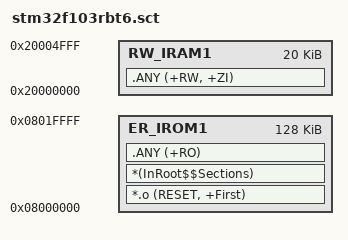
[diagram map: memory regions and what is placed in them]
; *************************************************************
; *** Scatter-Loading Description File generated by uVision ***
; *************************************************************

LR_IROM1 0x08000000 0x00020000  {    ; load region size_region  0x0003D000  0x0007D000
ER_IROM1 0x08000000 0x00020000  {  ; load address = execution address  0x0003D000  0x0007D000
   *.o (RESET, +First)
   *(InRoot$$Sections)
   .ANY (+RO)
  }
  RW_IRAM1 0x20000000 0x00005000  {  ; RW data  0x0000bff0  0x0000fff0
   .ANY (+RW, +ZI)
  }
}
